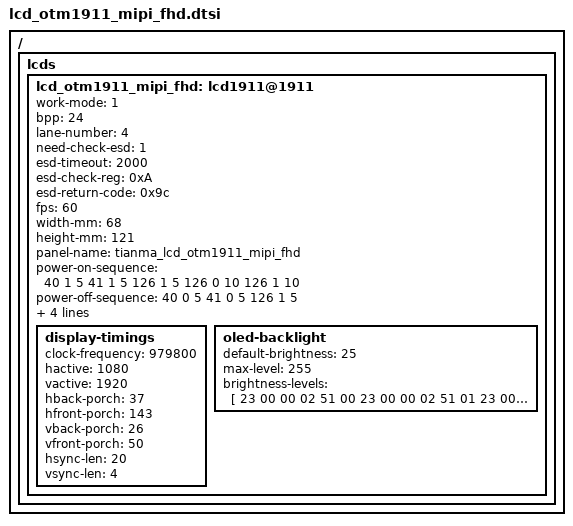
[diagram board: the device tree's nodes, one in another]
/ { lcds {
	lcd_otm1911_mipi_fhd: lcd1911@1911 {

		work-mode = <1>;
		bpp = <24>;
		lane-number = <4>;

		need-check-esd = <1>;
		esd-timeout = <2000>;
		esd-check-reg = <0xA>;
		esd-return-code = <0x9c>;

		fps = <60>;
		width-mm = <68>;
		height-mm = <121>;
		panel-name = "tianma_lcd_otm1911_mipi_fhd";

		power-on-sequence = <
				40  1  5
				41  1  5
				126  1  5
				126  0  10
				126  1  10
				>;
		power-off-sequence = <
				40  0  5
				41  0  5
				126  1  5
				>;

		init-data = [
			23 00 00 02 00 00
			29 0A 00 04 FF 19 11 01
			23 00 00 02 00 80
			29 0A 00 03 FF 19 11
			23 00 00 02 00 B0
			23 00 00 02 CA 00
			23 00 00 02 00 B5
			23 00 00 02 CA 04
			23 00 00 02 00 B2
			23 00 00 02 CA 0A
			23 00 00 02 00 00
			29 0A 00 04 FF 00 00 00
			29 05 00 03 51 00 00
			23 05 00 02 53 2c
			23 05 00 02 55 01
			13 78 00 01 11
			13 14 00 01 29
			];
		sleep-in = [
			13 0A 00 01 28
			13 78 00 01 10
			];
		sleep-out = [
			13 78 00 01 11
			13 32 00 01 29
			];
		display-timings {
			clock-frequency = <979800>;
			hactive = <1080>;
			vactive = <1920>;
			hback-porch = <37>;
			hfront-porch = <143>;
			vback-porch = <26>;
			vfront-porch = <50>;
			hsync-len = <20>;
			vsync-len = <4>;
		};
		oled-backlight {
			default-brightness = <25>;
			max-level = <255>;
			brightness-levels = [
				23 00 00 02 51 00
				23 00 00 02 51 01
				23 00 00 02 51 02
				23 00 00 02 51 03
				23 00 00 02 51 04
				23 00 00 02 51 05
				23 00 00 02 51 06
				23 00 00 02 51 07
				23 00 00 02 51 08
				23 00 00 02 51 09
				23 00 00 02 51 0A
				23 00 00 02 51 0A
				23 00 00 02 51 0B
				23 00 00 02 51 0B
				23 00 00 02 51 0C
				23 00 00 02 51 0C
				23 00 00 02 51 0D
				23 00 00 02 51 0D
				23 00 00 02 51 0E
				23 00 00 02 51 0E
				23 00 00 02 51 0F
				23 00 00 02 51 0F
				23 00 00 02 51 10
				23 00 00 02 51 11
				23 00 00 02 51 11
				23 00 00 02 51 12
				23 00 00 02 51 12
				23 00 00 02 51 13
				23 00 00 02 51 13
				23 00 00 02 51 14
				23 00 00 02 51 14
				23 00 00 02 51 15
				23 00 00 02 51 15
				23 00 00 02 51 16
				23 00 00 02 51 17
				23 00 00 02 51 17
				23 00 00 02 51 18
				23 00 00 02 51 18
				23 00 00 02 51 19
				23 00 00 02 51 19
				23 00 00 02 51 1A
				23 00 00 02 51 1A
				23 00 00 02 51 1B
				23 00 00 02 51 1B
				23 00 00 02 51 1C
				23 00 00 02 51 1D
				23 00 00 02 51 1D
				23 00 00 02 51 1E
				23 00 00 02 51 1E
				23 00 00 02 51 1F
				23 00 00 02 51 1F
				23 00 00 02 51 20
				23 00 00 02 51 20
				23 00 00 02 51 21
				23 00 00 02 51 21
				23 00 00 02 51 22
				23 00 00 02 51 23
				23 00 00 02 51 23
				23 00 00 02 51 24
				23 00 00 02 51 24
				23 00 00 02 51 25
				23 00 00 02 51 25
				23 00 00 02 51 26
				23 00 00 02 51 26
				23 00 00 02 51 27
				23 00 00 02 51 27
				23 00 00 02 51 28
				23 00 00 02 51 28
				23 00 00 02 51 29
				23 00 00 02 51 2A
				23 00 00 02 51 2A
				23 00 00 02 51 2B
				23 00 00 02 51 2B
				23 00 00 02 51 2C
				23 00 00 02 51 2C
				23 00 00 02 51 2D
				23 00 00 02 51 2D
				23 00 00 02 51 2E
				23 00 00 02 51 2E
				23 00 00 02 51 2F
				23 00 00 02 51 30
				23 00 00 02 51 30
				23 00 00 02 51 31
				23 00 00 02 51 31
				23 00 00 02 51 32
				23 00 00 02 51 32
				23 00 00 02 51 33
				23 00 00 02 51 33
				23 00 00 02 51 34
				23 00 00 02 51 34
				23 00 00 02 51 35
				23 00 00 02 51 36
				23 00 00 02 51 36
				23 00 00 02 51 37
				23 00 00 02 51 37
				23 00 00 02 51 38
				23 00 00 02 51 38
				23 00 00 02 51 39
				23 00 00 02 51 39
				23 00 00 02 51 3A
				23 00 00 02 51 3A
				23 00 00 02 51 3B
				23 00 00 02 51 3C
				23 00 00 02 51 3C
				23 00 00 02 51 3C
				23 00 00 02 51 3D
				23 00 00 02 51 3D
				23 00 00 02 51 3D
				23 00 00 02 51 3E
				23 00 00 02 51 3E
				23 00 00 02 51 3F
				23 00 00 02 51 3F
				23 00 00 02 51 3F
				23 00 00 02 51 40
				23 00 00 02 51 40
				23 00 00 02 51 41
				23 00 00 02 51 41
				23 00 00 02 51 41
				23 00 00 02 51 42
				23 00 00 02 51 42
				23 00 00 02 51 43
				23 00 00 02 51 43
				23 00 00 02 51 43
				23 00 00 02 51 44
				23 00 00 02 51 44
				23 00 00 02 51 45
				23 00 00 02 51 45
				23 00 00 02 51 46
				23 00 00 02 51 46
				23 00 00 02 51 47
				23 00 00 02 51 48
				23 00 00 02 51 49
				23 00 00 02 51 4A
				23 00 00 02 51 4B
				23 00 00 02 51 4C
				23 00 00 02 51 4C
				23 00 00 02 51 4D
				23 00 00 02 51 4E
				23 00 00 02 51 4F
				23 00 00 02 51 50
				23 00 00 02 51 51
				23 00 00 02 51 52
				23 00 00 02 51 52
				23 00 00 02 51 53
				23 00 00 02 51 54
				23 00 00 02 51 55
				23 00 00 02 51 56
				23 00 00 02 51 57
				23 00 00 02 51 58
				23 00 00 02 51 58
				23 00 00 02 51 59
				23 00 00 02 51 5A
				23 00 00 02 51 5B
				23 00 00 02 51 5C
				23 00 00 02 51 5D
				23 00 00 02 51 5E
				23 00 00 02 51 5E
				23 00 00 02 51 5F
				23 00 00 02 51 60
				23 00 00 02 51 61
				23 00 00 02 51 62
				23 00 00 02 51 63
				23 00 00 02 51 64
				23 00 00 02 51 64
				23 00 00 02 51 65
				23 00 00 02 51 66
				23 00 00 02 51 67
				23 00 00 02 51 68
				23 00 00 02 51 69
				23 00 00 02 51 6A
				23 00 00 02 51 6A
				23 00 00 02 51 6B
				23 00 00 02 51 6C
				23 00 00 02 51 6D
				23 00 00 02 51 6E
				23 00 00 02 51 6F
				23 00 00 02 51 70
				23 00 00 02 51 70
				23 00 00 02 51 71
				23 00 00 02 51 72
				23 00 00 02 51 73
				23 00 00 02 51 74
				23 00 00 02 51 75
				23 00 00 02 51 76
				23 00 00 02 51 76
				23 00 00 02 51 77
				23 00 00 02 51 78
				23 00 00 02 51 79
				23 00 00 02 51 7A
				23 00 00 02 51 7B
				23 00 00 02 51 7C
				23 00 00 02 51 7C
				23 00 00 02 51 7D
				23 00 00 02 51 7E
				23 00 00 02 51 7F
				23 00 00 02 51 80
				23 00 00 02 51 81
				23 00 00 02 51 82
				23 00 00 02 51 83
				23 00 00 02 51 83
				23 00 00 02 51 84
				23 00 00 02 51 85
				23 00 00 02 51 86
				23 00 00 02 51 87
				23 00 00 02 51 88
				23 00 00 02 51 89
				23 00 00 02 51 89
				23 00 00 02 51 8A
				23 00 00 02 51 8B
				23 00 00 02 51 8C
				23 00 00 02 51 8D
				23 00 00 02 51 8E
				23 00 00 02 51 8F
				23 00 00 02 51 8F
				23 00 00 02 51 90
				23 00 00 02 51 91
				23 00 00 02 51 92
				23 00 00 02 51 93
				23 00 00 02 51 94
				23 00 00 02 51 95
				23 00 00 02 51 95
				23 00 00 02 51 96
				23 00 00 02 51 97
				23 00 00 02 51 98
				23 00 00 02 51 99
				23 00 00 02 51 9A
				23 00 00 02 51 9B
				23 00 00 02 51 9B
				23 00 00 02 51 9C
				23 00 00 02 51 9D
				23 00 00 02 51 9E
				23 00 00 02 51 9F
				23 00 00 02 51 A0
				23 00 00 02 51 A1
				23 00 00 02 51 A1
				23 00 00 02 51 A2
				23 00 00 02 51 A3
				23 00 00 02 51 A4
				23 00 00 02 51 A5
				23 00 00 02 51 A6
				23 00 00 02 51 A7
				23 00 00 02 51 A7
				23 00 00 02 51 A8
				23 00 00 02 51 A9
				23 00 00 02 51 AA
				23 00 00 02 51 AB
				23 00 00 02 51 AC
				23 00 00 02 51 AD
				23 00 00 02 51 AD
				23 00 00 02 51 AE
				23 00 00 02 51 AF
				23 00 00 02 51 B0
				23 00 00 02 51 B1
				23 00 00 02 51 B2
				23 00 00 02 51 B3
				23 00 00 02 51 B4
			];
		};
	};
};};
